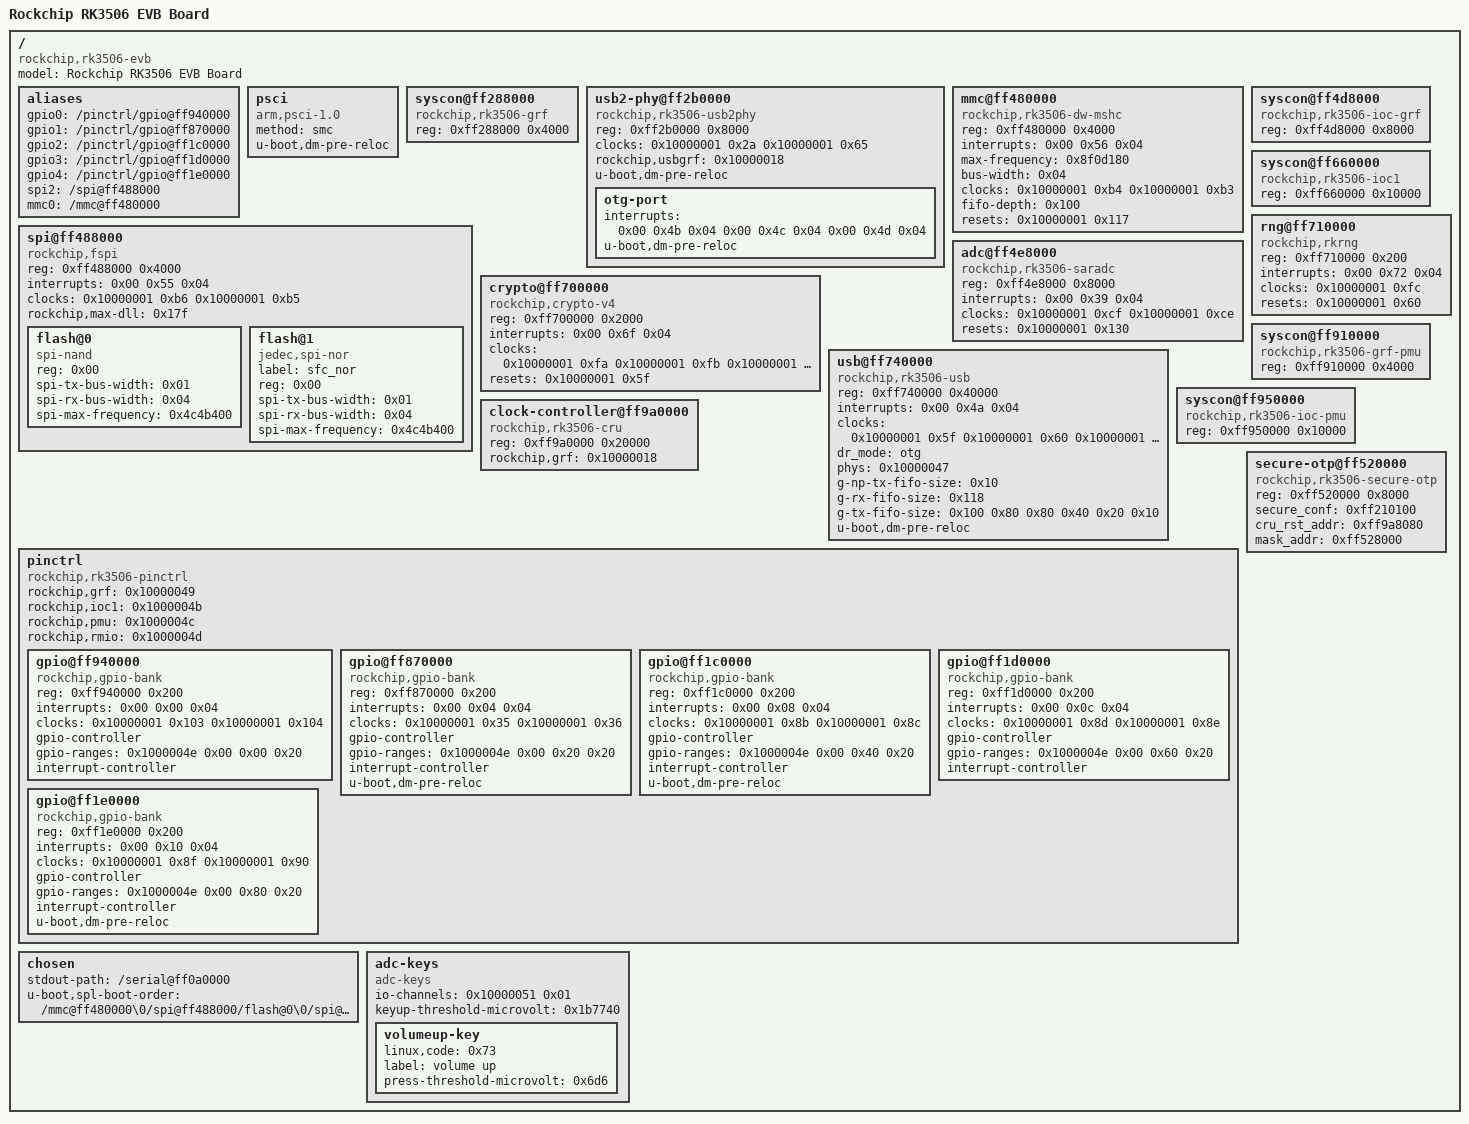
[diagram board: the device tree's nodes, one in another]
/dts-v1/;

/ {
	#address-cells = <0x01>;
	#size-cells = <0x01>;
	compatible = "rockchip,rk3506-evb\0rockchip,rk3506";
	model = "Rockchip RK3506 EVB Board";

	aliases {
		gpio0 = "/pinctrl/gpio@ff940000";
		gpio1 = "/pinctrl/gpio@ff870000";
		gpio2 = "/pinctrl/gpio@ff1c0000";
		gpio3 = "/pinctrl/gpio@ff1d0000";
		gpio4 = "/pinctrl/gpio@ff1e0000";
		spi2 = "/spi@ff488000";
		mmc0 = "/mmc@ff480000";
	};

	psci {
		compatible = "arm,psci-1.0";
		method = "smc";
		u-boot,dm-pre-reloc;
		status = "okay";
	};

	syscon@ff288000 {
		compatible = "rockchip,rk3506-grf\0syscon\0simple-mfd";
		reg = <0xff288000 0x4000>;
		u-boot,dm-spl;
		status = "okay";
		phandle = <0x10000018>;
	};

	usb2-phy@ff2b0000 {
		compatible = "rockchip,rk3506-usb2phy";
		reg = <0xff2b0000 0x8000>;
		clocks = <0x10000001 0x2a 0x10000001 0x65>;
		clock-names = "phyclk\0apb_pclk";
		#clock-cells = <0x00>;
		rockchip,usbgrf = <0x10000018>;
		status = "okay";
		u-boot,dm-pre-reloc;

		otg-port {
			#phy-cells = <0x00>;
			interrupts = <0x00 0x4b 0x04 0x00 0x4c 0x04 0x00 0x4d 0x04>;
			interrupt-names = "otg-bvalid\0otg-id\0linestate";
			status = "okay";
			u-boot,dm-pre-reloc;
			phandle = <0x10000047>;
		};
	};

	mmc@ff480000 {
		compatible = "rockchip,rk3506-dw-mshc\0rockchip,rk3288-dw-mshc";
		reg = <0xff480000 0x4000>;
		interrupts = <0x00 0x56 0x04>;
		max-frequency = <0x8f0d180>;
		bus-width = <0x04>;
		clocks = <0x10000001 0xb4 0x10000001 0xb3>;
		clock-names = "biu\0ciu";
		fifo-depth = <0x100>;
		resets = <0x10000001 0x117>;
		reset-names = "reset";
		status = "okay";
		u-boot,dm-spl;
	};

	spi@ff488000 {
		compatible = "rockchip,fspi";
		reg = <0xff488000 0x4000>;
		interrupts = <0x00 0x55 0x04>;
		clocks = <0x10000001 0xb6 0x10000001 0xb5>;
		clock-names = "clk_sfc\0hclk_sfc";
		rockchip,max-dll = <0x17f>;
		#address-cells = <0x01>;
		#size-cells = <0x00>;
		status = "okay";
		u-boot,dm-spl;

		flash@0 {
			u-boot,dm-spl;
			compatible = "spi-nand";
			reg = <0x00>;
			spi-tx-bus-width = <0x01>;
			spi-rx-bus-width = <0x04>;
			spi-max-frequency = <0x4c4b400>;
		};

		flash@1 {
			u-boot,dm-spl;
			compatible = "jedec,spi-nor";
			label = "sfc_nor";
			reg = <0x00>;
			spi-tx-bus-width = <0x01>;
			spi-rx-bus-width = <0x04>;
			spi-max-frequency = <0x4c4b400>;
		};
	};

	syscon@ff4d8000 {
		compatible = "rockchip,rk3506-ioc-grf\0syscon";
		reg = <0xff4d8000 0x8000>;
		u-boot,dm-spl;
		status = "okay";
		phandle = <0x10000049>;
	};

	adc@ff4e8000 {
		compatible = "rockchip,rk3506-saradc\0rockchip,rk3562-saradc";
		reg = <0xff4e8000 0x8000>;
		interrupts = <0x00 0x39 0x04>;
		#io-channel-cells = <0x01>;
		clocks = <0x10000001 0xcf 0x10000001 0xce>;
		clock-names = "saradc\0apb_pclk";
		resets = <0x10000001 0x130>;
		reset-names = "saradc-apb";
		status = "okay";
		u-boot,dm-spl;
		phandle = <0x10000051>;
	};

	syscon@ff660000 {
		compatible = "rockchip,rk3506-ioc1\0syscon";
		reg = <0xff660000 0x10000>;
		u-boot,dm-spl;
		status = "okay";
		phandle = <0x1000004b>;
	};

	crypto@ff700000 {
		compatible = "rockchip,crypto-v4";
		reg = <0xff700000 0x2000>;
		interrupts = <0x00 0x6f 0x04>;
		clocks = <0x10000001 0xfa 0x10000001 0xfb 0x10000001 0xf8 0x10000001 0xf9>;
		clock-names = "aclk\0hclk\0core\0pka";
		resets = <0x10000001 0x5f>;
		reset-names = "crypto-rst";
		status = "okay";
		u-boot,dm-spl;
	};

	rng@ff710000 {
		compatible = "rockchip,rkrng";
		reg = <0xff710000 0x200>;
		interrupts = <0x00 0x72 0x04>;
		clocks = <0x10000001 0xfc>;
		clock-names = "hclk_trng";
		resets = <0x10000001 0x60>;
		reset-names = "reset";
		status = "okay";
		u-boot,dm-spl;
	};

	usb@ff740000 {
		compatible = "rockchip,rk3506-usb\0rockchip,rk3066-usb\0snps,dwc2";
		reg = <0xff740000 0x40000>;
		interrupts = <0x00 0x4a 0x04>;
		clocks = <0x10000001 0x5f 0x10000001 0x60 0x10000001 0x61>;
		clock-names = "otg\0pmu\0adp";
		dr_mode = "otg";
		phys = <0x10000047>;
		phy-names = "usb2-phy";
		g-np-tx-fifo-size = <0x10>;
		g-rx-fifo-size = <0x118>;
		g-tx-fifo-size = <0x100 0x80 0x80 0x40 0x20 0x10>;
		status = "okay";
		u-boot,dm-pre-reloc;
	};

	syscon@ff910000 {
		compatible = "rockchip,rk3506-grf-pmu\0syscon\0simple-mfd";
		reg = <0xff910000 0x4000>;
		u-boot,dm-spl;
		status = "okay";
		phandle = <0x1000004d>;
	};

	syscon@ff950000 {
		compatible = "rockchip,rk3506-ioc-pmu\0syscon";
		reg = <0xff950000 0x10000>;
		u-boot,dm-spl;
		status = "okay";
		phandle = <0x1000004c>;
	};

	clock-controller@ff9a0000 {
		compatible = "rockchip,rk3506-cru";
		reg = <0xff9a0000 0x20000>;
		rockchip,grf = <0x10000018>;
		#clock-cells = <0x01>;
		#reset-cells = <0x01>;
		u-boot,dm-spl;
		status = "okay";
		phandle = <0x10000001>;
	};

	pinctrl {
		compatible = "rockchip,rk3506-pinctrl";
		rockchip,grf = <0x10000049>;
		rockchip,ioc1 = <0x1000004b>;
		rockchip,pmu = <0x1000004c>;
		rockchip,rmio = <0x1000004d>;
		#address-cells = <0x01>;
		#size-cells = <0x01>;
		ranges;
		u-boot,dm-spl;
		status = "okay";
		phandle = <0x1000004e>;

		gpio@ff940000 {
			compatible = "rockchip,gpio-bank";
			reg = <0xff940000 0x200>;
			interrupts = <0x00 0x00 0x04>;
			clocks = <0x10000001 0x103 0x10000001 0x104>;
			gpio-controller;
			#gpio-cells = <0x02>;
			gpio-ranges = <0x1000004e 0x00 0x00 0x20>;
			interrupt-controller;
			#interrupt-cells = <0x02>;
			u-boot,dm-spl;
			status = "okay";
		};

		gpio@ff870000 {
			compatible = "rockchip,gpio-bank";
			reg = <0xff870000 0x200>;
			interrupts = <0x00 0x04 0x04>;
			clocks = <0x10000001 0x35 0x10000001 0x36>;
			gpio-controller;
			#gpio-cells = <0x02>;
			gpio-ranges = <0x1000004e 0x00 0x20 0x20>;
			interrupt-controller;
			#interrupt-cells = <0x02>;
			u-boot,dm-pre-reloc;
			status = "okay";
		};

		gpio@ff1c0000 {
			compatible = "rockchip,gpio-bank";
			reg = <0xff1c0000 0x200>;
			interrupts = <0x00 0x08 0x04>;
			clocks = <0x10000001 0x8b 0x10000001 0x8c>;
			gpio-controller;
			#gpio-cells = <0x02>;
			gpio-ranges = <0x1000004e 0x00 0x40 0x20>;
			interrupt-controller;
			#interrupt-cells = <0x02>;
			u-boot,dm-pre-reloc;
			status = "okay";
		};

		gpio@ff1d0000 {
			compatible = "rockchip,gpio-bank";
			reg = <0xff1d0000 0x200>;
			interrupts = <0x00 0x0c 0x04>;
			clocks = <0x10000001 0x8d 0x10000001 0x8e>;
			gpio-controller;
			#gpio-cells = <0x02>;
			gpio-ranges = <0x1000004e 0x00 0x60 0x20>;
			interrupt-controller;
			#interrupt-cells = <0x02>;
			u-boot,dm-spl;
			status = "okay";
		};

		gpio@ff1e0000 {
			compatible = "rockchip,gpio-bank";
			reg = <0xff1e0000 0x200>;
			interrupts = <0x00 0x10 0x04>;
			clocks = <0x10000001 0x8f 0x10000001 0x90>;
			gpio-controller;
			#gpio-cells = <0x02>;
			gpio-ranges = <0x1000004e 0x00 0x80 0x20>;
			interrupt-controller;
			#interrupt-cells = <0x02>;
			u-boot,dm-pre-reloc;
			status = "okay";
		};
	};

	chosen {
		stdout-path = "/serial@ff0a0000";
		u-boot,spl-boot-order = "/mmc@ff480000\0/spi@ff488000/flash@0\0/spi@ff488000/flash@1";
	};

	secure-otp@ff520000 {
		compatible = "rockchip,rk3506-secure-otp";
		reg = <0xff520000 0x8000>;
		secure_conf = <0xff210100>;
		cru_rst_addr = <0xff9a8080>;
		mask_addr = <0xff528000>;
		u-boot,dm-spl;
		status = "okay";
	};

	adc-keys {
		compatible = "adc-keys";
		io-channels = <0x10000051 0x01>;
		io-channel-names = "buttons";
		keyup-threshold-microvolt = <0x1b7740>;
		u-boot,dm-spl;
		status = "okay";

		volumeup-key {
			u-boot,dm-spl;
			linux,code = <0x73>;
			label = "volume up";
			press-threshold-microvolt = <0x6d6>;
		};
	};
};
